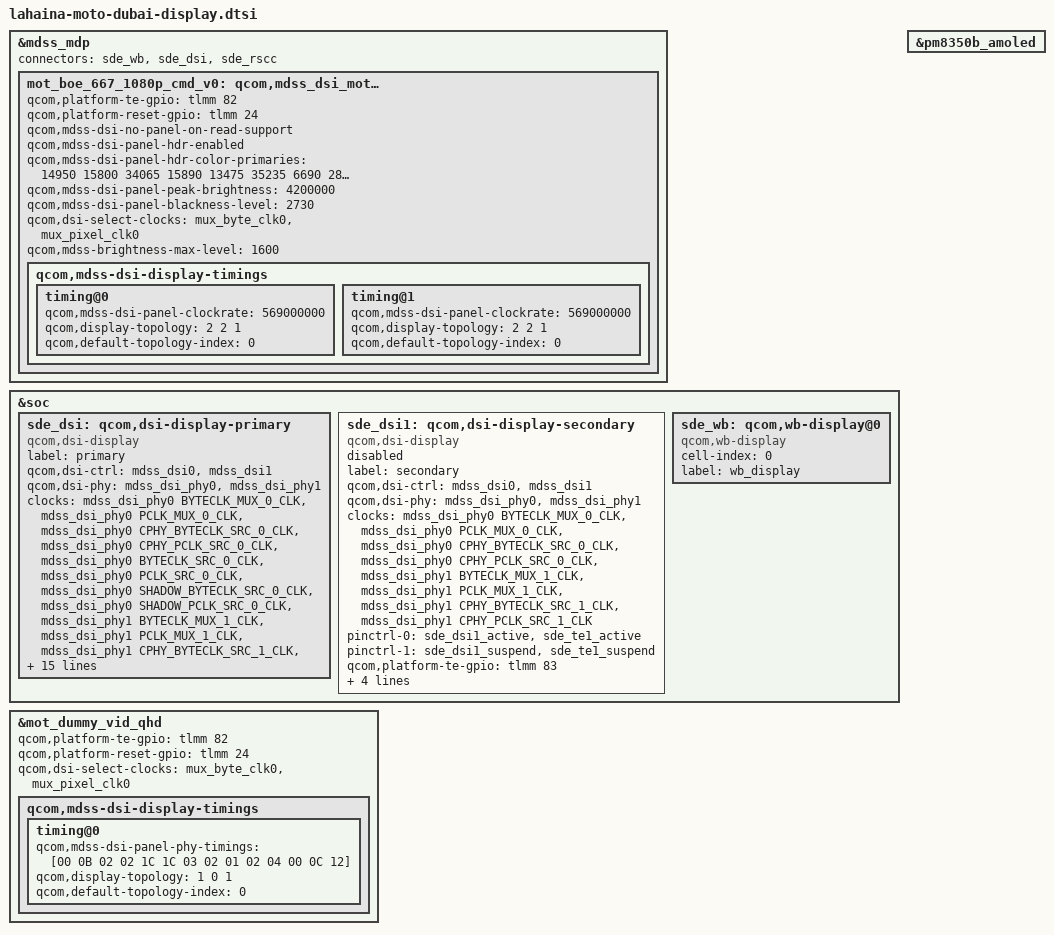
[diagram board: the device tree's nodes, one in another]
/* Copyright (c) 2019, The Linux Foundation. All rights reserved.
 *
 * This program is free software; you can redistribute it and/or modify
 * it under the terms of the GNU General Public License version 2 and
 * only version 2 as published by the Free Software Foundation.
 *
 * This program is distributed in the hope that it will be useful,
 * but WITHOUT ANY WARRANTY; without even the implied warranty of
 * MERCHANTABILITY or FITNESS FOR A PARTICULAR PURPOSE.  See the
 * GNU General Public License for more details.
 */

#include <dt-bindings/clock/mdss-5nm-pll-clk.h>
#include "dsi-panel-mot-dummy-qhd-video.dtsi"

&mdss_mdp {
	connectors = <&sde_wb &sde_dsi &sde_rscc>;

	mot_boe_667_1080p_cmd_v0: qcom,mdss_dsi_mot_boe_667_1080p_cmd_v0 {
		#include "dsi-panel-mot-boe-667-1080p-racer-cmd-common.dtsi"
	};
};

&soc {
	sde_dsi: qcom,dsi-display-primary {
		compatible = "qcom,dsi-display";
		label = "primary";

		qcom,dsi-ctrl = <&mdss_dsi0 &mdss_dsi1>;
		qcom,dsi-phy = <&mdss_dsi_phy0 &mdss_dsi_phy1>;

		clocks = <&mdss_dsi_phy0 BYTECLK_MUX_0_CLK>,
				 <&mdss_dsi_phy0 PCLK_MUX_0_CLK>,
				 <&mdss_dsi_phy0 CPHY_BYTECLK_SRC_0_CLK>,
				 <&mdss_dsi_phy0 CPHY_PCLK_SRC_0_CLK>,
				 <&mdss_dsi_phy0 BYTECLK_SRC_0_CLK>,
				 <&mdss_dsi_phy0 PCLK_SRC_0_CLK>,
				 <&mdss_dsi_phy0 SHADOW_BYTECLK_SRC_0_CLK>,
				 <&mdss_dsi_phy0 SHADOW_PCLK_SRC_0_CLK>,
				 <&mdss_dsi_phy1 BYTECLK_MUX_1_CLK>,
				 <&mdss_dsi_phy1 PCLK_MUX_1_CLK>,
				 <&mdss_dsi_phy1 CPHY_BYTECLK_SRC_1_CLK>,
				 <&mdss_dsi_phy1 CPHY_PCLK_SRC_1_CLK>,
				 <&mdss_dsi_phy1 BYTECLK_SRC_1_CLK>,
				 <&mdss_dsi_phy1 PCLK_SRC_1_CLK>,
				 <&mdss_dsi_phy1 SHADOW_BYTECLK_SRC_1_CLK>,
				 <&mdss_dsi_phy1 SHADOW_PCLK_SRC_1_CLK>;
		clock-names = "mux_byte_clk0", "mux_pixel_clk0",
				"cphy_byte_clk0", "cphy_pixel_clk0",
				"src_byte_clk0", "src_pixel_clk0",
				"shadow_byte_clk0", "shadow_pixel_clk0",
				"mux_byte_clk1", "mux_pixel_clk1",
				"cphy_byte_clk1", "cphy_pixel_clk1",
				"src_byte_clk1", "src_pixel_clk1",
				"shadow_byte_clk1", "shadow_pixel_clk1";

		pinctrl-names = "panel_active", "panel_suspend";
		pinctrl-0 = <&sde_dsi_active &sde_te_active>;
		pinctrl-1 = <&sde_dsi_suspend &sde_te_suspend>;

		qcom,platform-te-gpio = <&tlmm 82 0>;
		qcom,panel-te-source = <0>;

		vddio-supply = <&L12C>;
		vdd-supply = <&L13C>;

		qcom,mdp = <&mdss_mdp>;
		qcom,dsi-default-panel = <&mot_boe_667_1080p_cmd_v0>;
		qcom,platform-mot-ext-feature-enable;
	};
	sde_dsi1: qcom,dsi-display-secondary {
		compatible = "qcom,dsi-display";
		label = "secondary";

		qcom,dsi-ctrl = <&mdss_dsi0 &mdss_dsi1>;
		qcom,dsi-phy = <&mdss_dsi_phy0 &mdss_dsi_phy1>;

		clocks = <&mdss_dsi_phy0 BYTECLK_MUX_0_CLK>,
			 <&mdss_dsi_phy0 PCLK_MUX_0_CLK>,
			 <&mdss_dsi_phy0 CPHY_BYTECLK_SRC_0_CLK>,
			 <&mdss_dsi_phy0 CPHY_PCLK_SRC_0_CLK>,
			 <&mdss_dsi_phy1 BYTECLK_MUX_1_CLK>,
			 <&mdss_dsi_phy1 PCLK_MUX_1_CLK>,
			 <&mdss_dsi_phy1 CPHY_BYTECLK_SRC_1_CLK>,
			 <&mdss_dsi_phy1 CPHY_PCLK_SRC_1_CLK>;
		clock-names = "mux_byte_clk0", "mux_pixel_clk0",
				"cphy_byte_clk0", "cphy_pixel_clk0",
				"mux_byte_clk1", "mux_pixel_clk1",
				"cphy_byte_clk1", "cphy_pixel_clk1";

		pinctrl-names = "panel_active", "panel_suspend";
		pinctrl-0 = <&sde_dsi1_active &sde_te1_active>;
		pinctrl-1 = <&sde_dsi1_suspend &sde_te1_suspend>;

		qcom,platform-te-gpio = <&tlmm 83 0>;
		qcom,panel-te-source = <1>;

		vddio-supply = <&L12C>;
		vdd-supply = <&L13C>;
		//avdd-supply = <&display_panel_avdd>;

		qcom,mdp = <&mdss_mdp>;
	};
	sde_wb: qcom,wb-display@0 {
		compatible = "qcom,wb-display";
		cell-index = <0>;
		label = "wb_display";
	};
};

&sde_dsi1 {
	status = "disabled";
};

&pm8350b_amoled {
	status = "ok";
};


&mot_boe_667_1080p_cmd_v0 {
	qcom,platform-te-gpio = <&tlmm 82 0>;
	qcom,platform-reset-gpio = <&tlmm 24 0>;
	//qcom,panel-supply-entries = <&dsi_panel_pwr_supply>;
	qcom,mdss-dsi-no-panel-on-read-support;

	qcom,mdss-dsi-panel-hdr-enabled;
	qcom,mdss-dsi-panel-hdr-color-primaries = <14950 15800 34065
		15890 13475 35235 6690 2885>;
	qcom,mdss-dsi-panel-peak-brightness = <4200000>;
	qcom,mdss-dsi-panel-blackness-level = <2730>;
	qcom,dsi-select-clocks = "mux_byte_clk0", "mux_pixel_clk0";
	qcom,mdss-brightness-max-level = <1600>;
	qcom,mdss-dsi-display-timings {
		timing@0 {
			qcom,mdss-dsi-panel-clockrate = <569000000>;
			qcom,display-topology = <2 2 1>;
			qcom,default-topology-index = <0>;
		};
		timing@1 {
			qcom,mdss-dsi-panel-clockrate = <569000000>;
			qcom,display-topology = <2 2 1>;
			qcom,default-topology-index = <0>;
		};
	};
};

&mot_dummy_vid_qhd {
	qcom,platform-te-gpio = <&tlmm 82 0>;
	qcom,platform-reset-gpio = <&tlmm 24 0>;

	qcom,dsi-select-clocks = "mux_byte_clk0", "mux_pixel_clk0";
	qcom,mdss-dsi-display-timings {
		timing@0 {
			qcom,mdss-dsi-panel-phy-timings = [00 0B 02 02 1C 1C 03
							02 01 02 04 00 0C 12];
			qcom,display-topology = <1 0 1>;
			qcom,default-topology-index = <0>;
		};
	};
};
